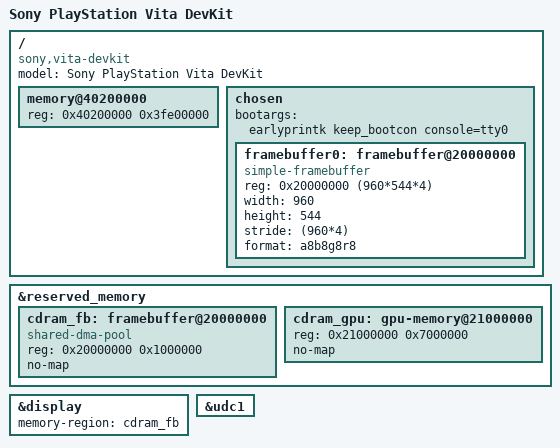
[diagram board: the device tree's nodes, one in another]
// SPDX-License-Identifier: GPL-2.0
/*
 * Device Tree Source for the PlayStation Vita DevKit (OLED, 1 GiB)
 */

/dts-v1/;

#include "vita.dtsi"

/ {
	model = "Sony PlayStation Vita DevKit";
	compatible = "sony,vita-devkit", "sony,vita", "vita,vita";

	/*
	 * 1 GiB on the DevKit: NSKBL uses 0x3FE00000 bytes from 0x40200000
	 * with SCE_DIPSW_ENABLE_TOOL_PHYMEMPART [WIKI Physical_Memory "1GiB DRAM
	 * for Development Kit"].
	 * Hardware info 0x00416000 [HW].
	 * The first 2 MiB (0x40000000-0x401FFFFF) are the secure world's.
	 */
	memory@40200000 {
		device_type = "memory";
		reg = <0x40200000 0x3fe00000>;
	};

	chosen {
		bootargs = "earlyprintk keep_bootcon console=tty0";

		/* Set up by the boot loader in CDRAM (0x20000000, 128 MiB) */
		framebuffer0: framebuffer@20000000 {
			compatible = "simple-framebuffer";
			reg = <0x20000000 (960*544*4)>;
			width = <960>;
			height = <544>;
			stride = <(960*4)>;
			format = "a8b8g8r8";
			status = "okay";
		};
	};
};

&reserved_memory {
	/*
	 * Scanout: the boot loader's 960x544x4 framebuffer at its start
	 * (simple-framebuffer), or the display driver's buffers (eight
	 * 960x544x4 buffers, each taking 2 MiB of the pool).
	 */
	cdram_fb: framebuffer@20000000 {
		compatible = "shared-dma-pool";
		reg = <0x20000000 0x1000000>;
		no-map;
	};

	/* The rest of CDRAM: the GPU's buffer objects */
	cdram_gpu: gpu-memory@21000000 {
		reg = <0x21000000 0x7000000>;
		no-map;
	};
};

/*
 * The OLED head. Disabled here: the boot loader enables it and removes the
 * simple-framebuffer for vita.display=native, and enables it next to the
 * simple-framebuffer for vita.display=handover.
 */
&display {
	memory-region = <&cdram_fb>;
};

/*
 * The mini-USB port, bus 1. Android's USB function stays on the
 * multi-connector (sys.usb.controller e40d0000.usb); this one is a second
 * gadget controller for configfs. Not verified on hardware.
 */
&udc1 {
	status = "okay";
};
